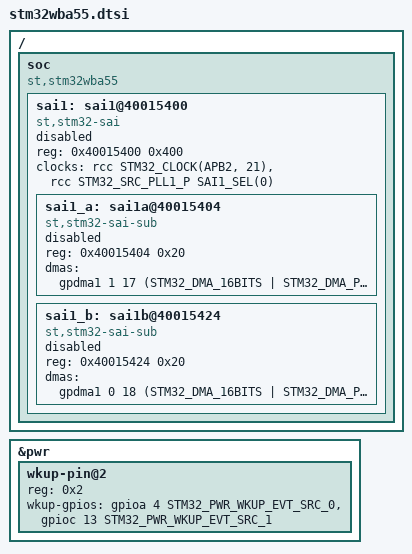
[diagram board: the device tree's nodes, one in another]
/*
 * Copyright (c) 2023 STMicroelectronics
 * Copyright (c) 2025 Mario Paja
 *
 * SPDX-License-Identifier: Apache-2.0
 */
#include <st/wba/stm32wba52.dtsi>

/ {
	soc {
		compatible = "st,stm32wba55", "st,stm32wba", "simple-bus";

		sai1: sai1@40015400 {
			compatible = "st,stm32-sai";
			#address-cells = <1>;
			#size-cells = <0>;
			reg = <0x40015400 0x400>;
			clocks = <&rcc STM32_CLOCK(APB2, 21)>,
				 <&rcc STM32_SRC_PLL1_P SAI1_SEL(0)>;
			status = "disabled";

			sai1_a: sai1a@40015404 {
				compatible = "st,stm32-sai-sub";
				reg = <0x40015404 0x20>;
				dmas = <&gpdma1 1 17 (STM32_DMA_16BITS | STM32_DMA_PRIORITY_HIGH)>;
				status = "disabled";
			};

			sai1_b: sai1b@40015424 {
				compatible = "st,stm32-sai-sub";
				reg = <0x40015424 0x20>;
				dmas = <&gpdma1 0 18 (STM32_DMA_16BITS | STM32_DMA_PRIORITY_HIGH)>;
				status = "disabled";
			};
		};
	};
};

&pwr {
	wkup-pin@2 {
		reg = <0x2>;
		wkup-gpios = <&gpioa 4 STM32_PWR_WKUP_EVT_SRC_0>,
			     <&gpioc 13 STM32_PWR_WKUP_EVT_SRC_1>;
	};
};
